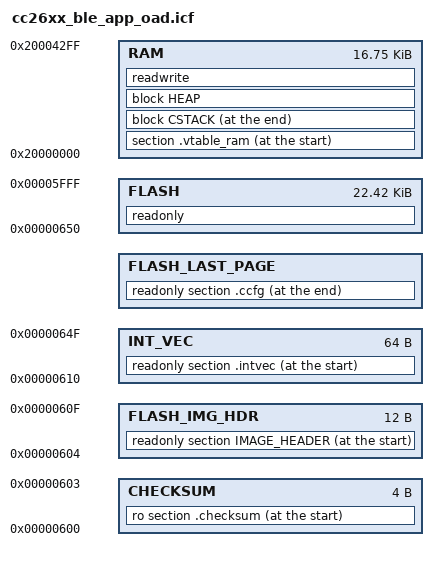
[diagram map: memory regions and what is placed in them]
/*******************************************************************************
  Filename:       cc26xx_ble_stack.icf
  Revised:        $Date: 2014-03-24 07:09:35 -0700 (Mon, 24 Mar 2014) $
  Revision:       $Revision: 37847 $

  Description:    IAR ARM Linker Configuration File - BLE Stack

  Note: Code stack and heap are allocated by the Application/RTOS build.

  Imported Symbols
  Note: Linker defines are located in the IAR IDE project using --config_def
        in Options->Linker->Extra Options, or placed in Options->Linker->
        Config->Configuration file symbol definitions.

  CCxxxx:            Device Name (e.g. CC2650).
  FLASH_ONLY_BUILD:  Build full BLE stack in flash only memory.
  FLASH_ROM_BUILD:   Build Flash portion of BLE stack to work with ROM code.
  ROM_BUILD:         Build ROM portion of BLE stack.
  COMMON_ROM_BUILD:  Build of common ROM code.
  TEST_ROM_IN_FLASH: Build ROM code in Flash memory to test.
  ICALL_STACK0_ADDR: Start address of flash only and flash ROM builds.

  Exported Symbols
  Note: Can be used as externs in C code.

  ROM_BASE_ADDR:        Location of start of ROM (where RT Init is expected).
  RAM_BASE_ADDR:        Location of start of RAM (for ICall and JT pointers).
  COMMON_RAM_BASE_ADDR: Location of start of RAM (for ICall and JT pointers).
  PAGE_SIZE:            Size of Flash sector, in bytes.
  NUM_SNV_PAGES:        Number of sectors used for Simple NV.

  Copyright 2013-2015 Texas Instruments Incorporated. All rights reserved.

  IMPORTANT: Your use of this Software is limited to those specific rights
  granted under the terms of a software license agreement between the user
  who downloaded the software, his/her employer (which must be your employer)
  and Texas Instruments Incorporated (the "License").  You may not use this
  Software unless you agree to abide by the terms of the License. The License
  limits your use, and you acknowledge, that the Software may not be modified,
  copied or distributed unless embedded on a Texas Instruments microcontroller
  or used solely and exclusively in conjunction with a Texas Instruments radio
  frequency transceiver, which is integrated into your product.  Other than for
  the foregoing purpose, you may not use, reproduce, copy, prepare derivative
  works of, modify, distribute, perform, display or sell this Software and/or
  its documentation for any purpose.

  YOU FURTHER ACKNOWLEDGE AND AGREE THAT THE SOFTWARE AND DOCUMENTATION ARE
  PROVIDED “AS IS” WITHOUT WARRANTY OF ANY KIND, EITHER EXPRESS OR IMPLIED,
  INCLUDING WITHOUT LIMITATION, ANY WARRANTY OF MERCHANTABILITY, TITLE,
  NON-INFRINGEMENT AND FITNESS FOR A PARTICULAR PURPOSE. IN NO EVENT SHALL
  TEXAS INSTRUMENTS OR ITS LICENSORS BE LIABLE OR OBLIGATED UNDER CONTRACT,
  NEGLIGENCE, STRICT LIABILITY, CONTRIBUTION, BREACH OF WARRANTY, OR OTHER
  LEGAL EQUITABLE THEORY ANY DIRECT OR INDIRECT DAMAGES OR EXPENSES
  INCLUDING BUT NOT LIMITED TO ANY INCIDENTAL, SPECIAL, INDIRECT, PUNITIVE
  OR CONSEQUENTIAL DAMAGES, LOST PROFITS OR LOST DATA, COST OF PROCUREMENT
  OF SUBSTITUTE GOODS, TECHNOLOGY, SERVICES, OR ANY CLAIMS BY THIRD PARTIES
  (INCLUDING BUT NOT LIMITED TO ANY DEFENSE THEREOF), OR OTHER SIMILAR COSTS.

  Should you have any questions regarding your right to use this Software,
  contact Texas Instruments Incorporated at www.TI.com.
*******************************************************************************/

////////////////////////////////////////////////////////////////////////////////
// Memory Sizes
////////////////////////////////////////////////////////////////////////////////

  define symbol RAM_SIZE            = 0x00005000;  // 20K
  define symbol FLASH_SIZE          = 0x00020000;  // 128K
  define symbol ROM_SIZE            = 0x0001C000;  // 115K

////////////////////////////////////////////////////////////////////////////////

////////////////////////////////////////////////////////////////////////////////
// Memory Definitions
////////////////////////////////////////////////////////////////////////////////

////////////////////////////////////////////////////////////////////////////////
// RAM
//

define symbol RAM_START             = 0x20000000;

  if ( isdefinedsymbol(ICALL_RAM0_ADDR) )
  {
    define symbol RAM_END           = (ICALL_RAM0_ADDR-1);
  }
  else // default
  {
    define symbol RAM_END           = 0x200042FF;
  }

////////////////////////////////////////////////////////////////////////////////
// Flash
//

if ( isdefinedsymbol(APP_IMAGE_START) )
{
  define symbol FLASH_START         = APP_IMAGE_START;
  
  // For the External Flash use case, ICALL_STACK0_ADDR may be used to determine
  // the end of the application's flash region
  if ( isdefinedsymbol(ICALL_STACK0_ADDR) )
  {
    define symbol IMAGE_SIZE = ICALL_STACK0_ADDR - (FLASH_START) - 1;
  }
  // Custom OAD Image sizes.
  else if ( isdefinedsymbol(APP_IMAGE_SIZE) )
  {
    define symbol IMAGE_SIZE        = APP_IMAGE_SIZE;
  }
  else
  {
    if ( isdefinedsymbol(RTOS_ROM) )
    {
      // Default for RTOS in ROM build.  This assumes that the application is
      // also using some space on page 31 (0x1F).
      define symbol IMAGE_SIZE      = 0x5000;
    }
    else
    {
      // Default RTOS in Flash build.  This is the maximum size for the larger
      // OAD image, assuming Stack image starts at address 0xF000.
      define symbol IMAGE_SIZE      = 0x9000;
    }
  }
  
  define symbol FLASH_END           = APP_IMAGE_START + IMAGE_SIZE - 1;
}
else
{
  if ( isdefinedsymbol(RTOS_ROM) )
  {
    // Default for OAD Image A region, RTOS in ROM size.
    define symbol FLASH_START         = 0x0600;
    define symbol FLASH_END           = 0x5FFF;
  }
  else
  {
    // Default for OAD Image B region, RTOS in Flash size.
    define symbol FLASH_START         = 0x00006000;
    define symbol FLASH_END           = FLASH_START + 0x8FFF;
  }
}

// OAD specific
define symbol OAD_HDR_SIZE    = 12; // linker needs word alignment.
define symbol OAD_HDR_START   = FLASH_START + 4;
define symbol OAD_HDR_END     = OAD_HDR_START + OAD_HDR_SIZE - 1;

define symbol INT_VEC_SIZE    = 64;
define symbol INT_VEC_START   = OAD_HDR_START + OAD_HDR_SIZE;
define symbol INT_VEC_END     = INT_VEC_START + INT_VEC_SIZE - 1;

define symbol OAD_FLASH_START = INT_VEC_START + INT_VEC_SIZE;

////////////////////////////////////////////////////////////////////////////////
// Stack
//

define symbol STACK_SIZE           = 0x400;
define symbol STACK_START          = RAM_END + 1;
define symbol STACK_END            = STACK_START - STACK_SIZE;
define block CSTACK with alignment = 8, size = STACK_SIZE { section .stack };
//
define symbol STACK_TOP            = RAM_END + 1;
export symbol STACK_TOP;

////////////////////////////////////////////////////////////////////////////////
// Heap
//

define symbol HEAP_SIZE            = 0x1000;
define block  HEAP with alignment  = 8, size = HEAP_SIZE { };

////////////////////////////////////////////////////////////////////////////////
// Flash Interrupt Vector Table
//

define symbol INTVEC_NUM_ENTRIES   = 50 + 1; // first entry is stack location
define symbol INTVEC_SIZE          = INTVEC_NUM_ENTRIES + 4;

////////////////////////////////////////////////////////////////////////////////
// Memory Regions
////////////////////////////////////////////////////////////////////////////////

define memory mem with size = 4G;

define region CHECKSUM        = mem:[from FLASH_START     to FLASH_START + 3];
define region FLASH_IMG_HDR   = mem:[from OAD_HDR_START   to OAD_HDR_END];
define region INT_VEC         = mem:[from INT_VEC_START   to INT_VEC_END];

// RTOS in ROM OAD image is fixed and can therefore use the extra space
// on page 31 (0x1F).
if ( isdefinedsymbol(RTOS_ROM) )
{
  define region FLASH_LAST_PAGE = mem:[from(FLASH_SIZE) - 0xA00 to FLASH_SIZE-1];
  define region FLASH           = mem:[from OAD_FLASH_START to FLASH_END]
                                  | FLASH_LAST_PAGE;
}
else
{
define region FLASH           = mem:[from OAD_FLASH_START to FLASH_END];
}

define region RAM             = mem:[from RAM_START       to RAM_END];

////////////////////////////////////////////////////////////////////////////////
// Memory Placement
// For ROM: C Runtime, Checksum, ROM Revision Number, Flash JT, and FPB.
////////////////////////////////////////////////////////////////////////////////
place at start of CHECKSUM      { ro section .checksum };
keep                            { ro section .checksum };

// Flash OAD Image Header
place at start of FLASH_IMG_HDR { readonly section IMAGE_HEADER };
keep                            { readonly section IMAGE_HEADER };

// CCA
if ( isdefinedsymbol(RTOS_ROM) )
{
  place at end of FLASH_LAST_PAGE { readonly section .ccfg };
  keep { section .ccfg};
}

// Interrupt Vector Table
place at start of INT_VEC       { readonly section .intvec };
keep                            { readonly section .intvec };

// RAM Vector Table
place at start of RAM           { section .vtable_ram };

// Stack
place at end of RAM             { block CSTACK };

// Heap
place in RAM                    { block HEAP };

place in FLASH                  { readonly };
place in RAM                    { readwrite };

////////////////////////////////////////////////////////////////////////////////
// Initialization
////////////////////////////////////////////////////////////////////////////////

initialize by copy { readwrite };

do not initialize
{
  section .noinit,
  section .stack,
};

////////////////////////////////////////////////////////////////////////////////
// The USE_TIRTOS_ROM symbol is defined internally in the build flow (using
// --config_def USE_TIRTOS_ROM=1) for TI-RTOS applications whose appBLE.cfg file
// specifies to use the ROM.
//
if (isdefinedsymbol(USE_TIRTOS_ROM)) {
     include "TIRTOS_ROM.icf";
}
